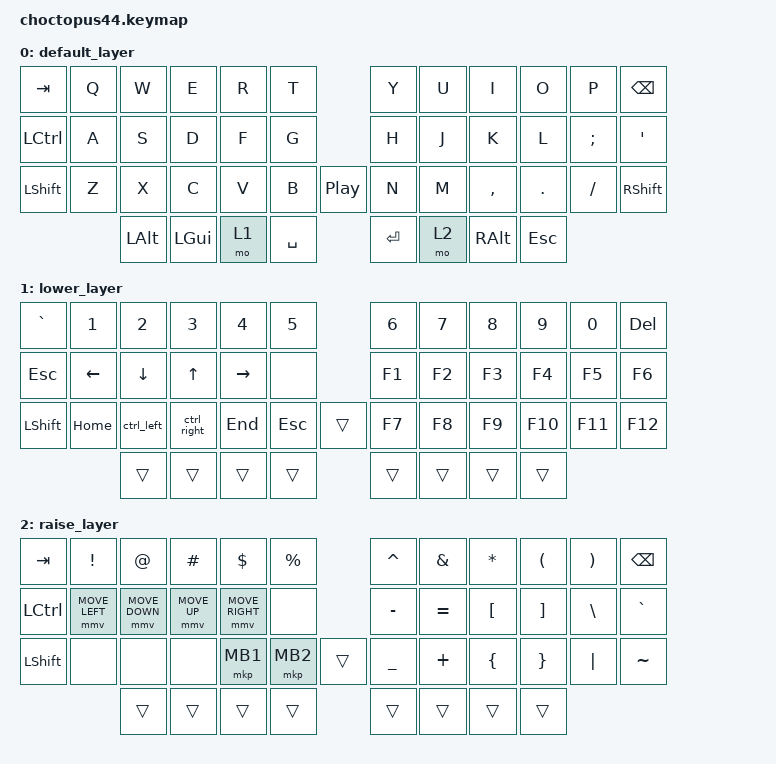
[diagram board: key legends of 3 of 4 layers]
/*
 * Copyright (c) 2021 The ZMK Contributors
 *
 * SPDX-License-Identifier: MIT
 */


#define ZMK_POINTING_DEFAULT_MOVE_VAL 1200  // default: 600
#define ZMK_POINTING_DEFAULT_SCRL_VAL 20

#include <behaviors.dtsi>
#include <dt-bindings/zmk/keys.h>
#include <dt-bindings/zmk/bt.h>
#include <dt-bindings/zmk/rgb.h>
// #include <behaviors/rgbled_widget.dtsi>
#include <dt-bindings/zmk/ext_power.h>
#include <dt-bindings/zmk/pointing.h>

&mt {
    tapping-term-ms = <400>;
};

/ {
    macros {
      ctrl_alt_home: ctrl_alt_home {
        compatible = "zmk,behavior-macro";
        #binding-cells = <0>;
        bindings = <&macro_press &kp LCTRL &kp LALT>,
                   <&macro_tap &kp HOME>,
                   <&macro_release &kp LCTRL &kp LALT>;
      };
      ctrl_win_left: ctrl_win_left {
        compatible = "zmk,behavior-macro";
        #binding-cells = <0>;
        bindings = <&macro_press &kp LCTRL &kp LGUI>,
                   <&macro_tap &kp LEFT>,
                   <&macro_release &kp LCTRL &kp LGUI>;
      };
      ctrl_win_right: ctrl_win_right {
        compatible = "zmk,behavior-macro";
        #binding-cells = <0>;
        bindings = <&macro_press &kp LCTRL &kp LGUI>,
                   <&macro_tap &kp RIGHT>,
                   <&macro_release &kp LCTRL &kp LGUI>;
      };
      ctrl_shift_esc: ctrl_shift_esc {
        compatible = "zmk,behavior-macro";
        #binding-cells = <0>;
        bindings = <&macro_press &kp LCTRL &kp LSHIFT>,
                   <&macro_tap &kp ESC>,
                   <&macro_release &kp LCTRL &kp LSHIFT>;
      };
      alt_f4: alt_f4 {
        compatible = "zmk,behavior-macro";
        #binding-cells = <0>;
        bindings = <&macro_press &kp LALT>,
                   <&macro_tap &kp F4>,
                   <&macro_release &kp LALT>;
      };
      ctrl_shift_r: ctrl_shift_r {
        compatible = "zmk,behavior-macro";
        #binding-cells = <0>;
        bindings = <&macro_press &kp LCTRL &kp LSHIFT>,
                   <&macro_tap &kp R>,
                   <&macro_release &kp LCTRL &kp LSHIFT>;
      };
      win_l: win_l {
        compatible = "zmk,behavior-macro";
        #binding-cells = <0>;
        bindings = <&macro_press &kp LGUI>,
                   <&macro_tap &kp L>,
                   <&macro_release &kp LGUI>;
      };
      ctrl_left: ctrl_left {
        compatible = "zmk,behavior-macro";
        #binding-cells = <0>;
        bindings = <&macro_press &kp LCTRL>,
                   <&macro_tap &kp LEFT>,
                   <&macro_release &kp LCTRL>;
      };
      ctrl_right: ctrl_right {
        compatible = "zmk,behavior-macro";
        #binding-cells = <0>;
        bindings = <&macro_press &kp LCTRL>,
                   <&macro_tap &kp RIGHT>,
                   <&macro_release &kp LCTRL>;
      };
  };
};

/ {
  conditional_layers {
    compatible = "zmk,conditional-layers";
    tri_layer {
      if-layers = <1 2>;
      then-layer = <3>;
    };
  };
};

/ {
  keymap {
    compatible = "zmk,keymap";
    compatible = "zmk,keymap";

    default_layer {
      // display_name = "default";
      bindings = <
&kp TAB         &kp Q           &kp W           &kp E           &kp R           &kp T                           &kp Y           &kp U           &kp I           &kp O           &kp P           &kp BSPC
&kp LCTRL       &kp A           &kp S           &kp D           &kp F           &kp G                           &kp H           &kp J           &kp K           &kp L           &kp SEMI        &kp SQT
&kp LSHFT       &kp Z           &kp X           &kp C           &kp V           &kp B          &kp C_PLAY_PAUSE &kp N           &kp M           &kp COMMA       &kp DOT         &kp FSLH        &kp RSHFT
                                &kp LALT        &kp LGUI        &mo 1           &kp SPACE                       &kp RET         &mo 2           &kp RALT        &kp ESC
      >;
      sensor-bindings = <&inc_dec_kp C_VOL_DN C_VOL_UP>;
    };
    lower_layer {
      // display-name = "lower";
      bindings = <
&kp GRAVE       &kp N1          &kp N2          &kp N3          &kp N4          &kp N5                          &kp N6          &kp N7          &kp N8          &kp N9          &kp N0          &kp DEL
&kp ESC         &kp LEFT        &kp DOWN        &kp UP          &kp RIGHT       &none                           &kp F1          &kp F2          &kp F3          &kp F4          &kp F5          &kp F6
&kp LSHFT       &kp HOME        &ctrl_left      &ctrl_right     &kp END         &kp ESC         &trans          &kp F7          &kp F8          &kp F9          &kp F10         &kp F11         &kp F12
                                &trans          &trans          &trans          &trans                          &trans          &trans          &trans          &trans
      >;
      sensor-bindings = <&inc_dec_kp C_VOL_DN C_VOL_UP>;
    };
    raise_layer {
      // display-name = "raise";
      bindings = <
&kp TAB         &kp EXCL        &kp AT          &kp HASH        &kp DLLR        &kp PRCNT                       &kp CARET       &kp AMPS        &kp ASTRK       &kp LPAR        &kp RPAR       &kp BSPC
&kp LCTRL       &mmv MOVE_LEFT  &mmv MOVE_DOWN  &mmv MOVE_UP    &mmv MOVE_RIGHT &none                           &kp MINUS       &kp EQUAL       &kp LBKT        &kp RBKT        &kp BSLH       &kp GRAVE
&kp LSHFT       &none           &none           &none           &mkp MB1        &mkp MB2        &trans          &kp UNDER       &kp PLUS        &kp LBRC        &kp RBRC        &kp PIPE       &kp TILDE
                                &trans          &trans          &trans          &trans                          &trans          &trans          &trans          &trans
      >;
      sensor-bindings = <&inc_dec_kp C_VOL_DN C_VOL_UP>;
    };
    adjust_layer {
      // display-name = "adjust";
      bindings = <
&bt BT_SEL 0    &bt BT_SEL 1    &bt BT_SEL 2    &bt BT_SEL 3    &bt BT_SEL 4    &none                           &soft_off       &none           &none           &none           &none           &bt BT_CLR
&none           &none           &none           &none           &none           &none                           &kp PSCRN       &none           &none           &none           &none           &none
&none           &none           &none           &kp C_VOL_DN    &kp C_VOL_UP    &kp C_PP        &trans          &ctrl_alt_home  &ctrl_win_left  &ctrl_win_right &none           &none           &none
                                                &none           &trans          &none                           &none           &trans          &none           &none
      >;
      sensor-bindings = <&inc_dec_kp C_VOL_DN C_VOL_UP>;
    };
  };
};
